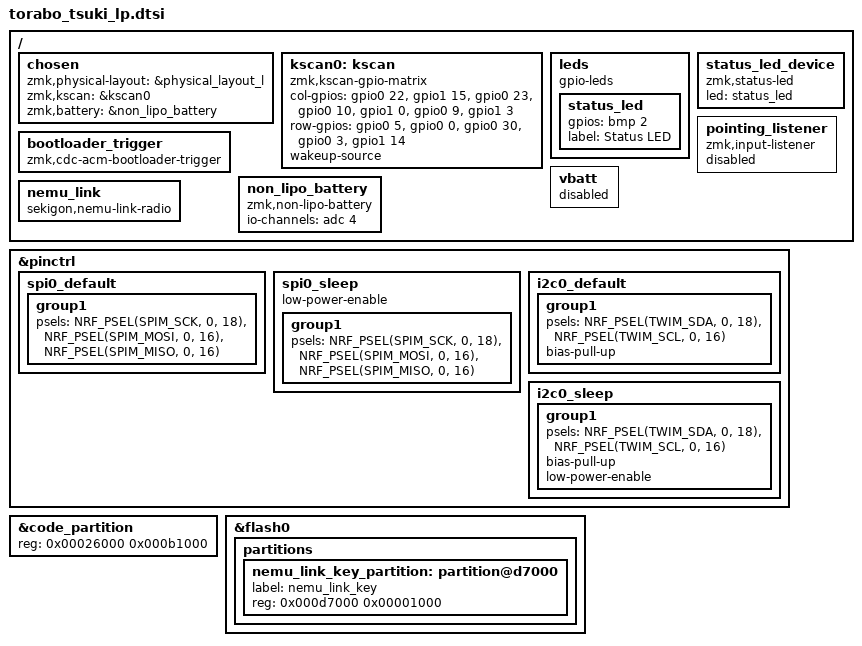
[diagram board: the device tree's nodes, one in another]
#include <zephyr/dt-bindings/gpio/nordic-nrf-gpio.h>
#include <dt-bindings/zmk/matrix_transform.h>
#include "torabo_tsuki_lp_layouts.dtsi"
#include "torabo_tsuki_lp_layout_transforms.dtsi"
#include "torabo_tsuki_lp_shared_settings.dtsi"

/ {
    chosen {
        zmk,physical-layout = &physical_layout_l;
        zmk,kscan = &kscan0;
        zmk,battery = &non_lipo_battery;
    };

    kscan0: kscan {
        compatible = "zmk,kscan-gpio-matrix";

        col-gpios
            = <&gpio0 22 (GPIO_ACTIVE_HIGH | GPIO_PULL_DOWN)>,
            <&gpio1 15   (GPIO_ACTIVE_HIGH | GPIO_PULL_DOWN)>,
            <&gpio0 23   (GPIO_ACTIVE_HIGH | GPIO_PULL_DOWN)>,
            <&gpio0 10   (GPIO_ACTIVE_HIGH | GPIO_PULL_DOWN)>,
            <&gpio1 0    (GPIO_ACTIVE_HIGH | GPIO_PULL_DOWN)>,
            <&gpio0 9    (GPIO_ACTIVE_HIGH | GPIO_PULL_DOWN)>,
            <&gpio1 3    (GPIO_ACTIVE_HIGH | GPIO_PULL_DOWN)>
            ;

        row-gpios
            = <&gpio0 5 (GPIO_ACTIVE_HIGH)>,
            <&gpio0 0  (GPIO_ACTIVE_HIGH)>,
            <&gpio0 30 (GPIO_ACTIVE_HIGH)>,
            <&gpio0 3  (GPIO_ACTIVE_HIGH)>,
            <&gpio1 14 (GPIO_ACTIVE_HIGH)>
        ;

        wakeup-source;
    };

    leds {
        compatible = "gpio-leds";
        status_led: status_led {
            gpios = <&bmp 2 GPIO_ACTIVE_HIGH>;
            label = "Status LED";
        };
    };

    status_led_device: status_led_device {
        compatible = "zmk,status-led";
        led = <&status_led>;
    };

    bootloader_trigger: bootloader_trigger {
        compatible = "zmk,cdc-acm-bootloader-trigger";
    };

    pointing_listener: pointing_listener {
        compatible = "zmk,input-listener";
        status = "disabled";
    };

    vbatt: vbatt {
        // Disable default battery monitoring
        status = "disabled";
    };
    non_lipo_battery: non_lipo_battery {
        compatible = "zmk,non-lipo-battery";
        io-channels = <&adc 4>; 
    };

    nemu_link {
        compatible = "sekigon,nemu-link-radio";
    };
};
&pinctrl {
    spi0_default: spi0_default {
        group1 {
            psels = <NRF_PSEL(SPIM_SCK, 0, 18)>,
                    <NRF_PSEL(SPIM_MOSI, 0, 16)>,
                    <NRF_PSEL(SPIM_MISO, 0, 16)>;
        };
    };

    spi0_sleep: spi0_sleep {
        group1 {
            psels = <NRF_PSEL(SPIM_SCK, 0, 18)>,
                    <NRF_PSEL(SPIM_MOSI, 0, 16)>,
                    <NRF_PSEL(SPIM_MISO, 0, 16)>;
        };
        low-power-enable;
    };

    i2c0_default: i2c0_default {
        group1 {
            psels = <NRF_PSEL(TWIM_SDA, 0, 18)>,
                    <NRF_PSEL(TWIM_SCL, 0, 16)>;
            bias-pull-up;
        };
    };

    i2c0_sleep: i2c0_sleep {
        group1 {
            psels = <NRF_PSEL(TWIM_SDA, 0, 18)>,
                    <NRF_PSEL(TWIM_SCL, 0, 16)>;
            bias-pull-up;
            low-power-enable;
        };
    };
};

// trackball and trackpad are defined in the snippets

&code_partition {
    reg = <0x00026000 0x000b1000>;
};

&flash0 {
    partitions {
        nemu_link_key_partition: partition@d7000 {
            label = "nemu_link_key";
            reg = <0x000d7000 0x00001000>;
        };
    };
};
